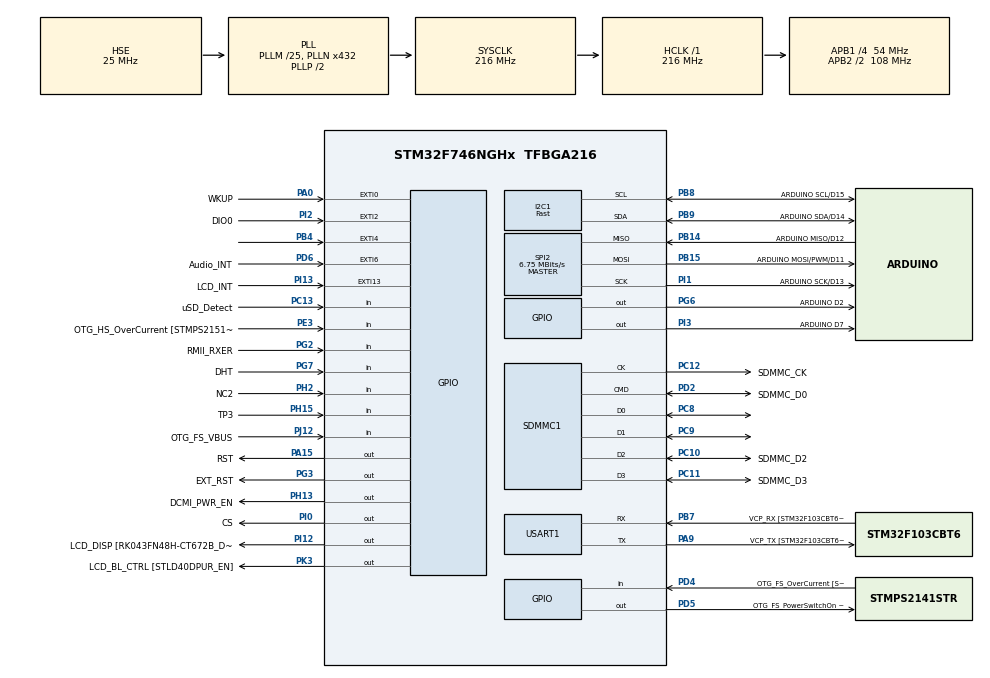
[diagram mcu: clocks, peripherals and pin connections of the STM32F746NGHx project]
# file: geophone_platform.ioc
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Dma.I2C1_RX.0.Direction=DMA_PERIPH_TO_MEMORY
Dma.I2C1_RX.0.FIFOMode=DMA_FIFOMODE_DISABLE
Dma.I2C1_RX.0.Instance=DMA1_Stream0
Dma.I2C1_RX.0.MemDataAlignment=DMA_MDATAALIGN_BYTE
Dma.I2C1_RX.0.MemInc=DMA_MINC_ENABLE
Dma.I2C1_RX.0.Mode=DMA_NORMAL
Dma.I2C1_RX.0.PeriphDataAlignment=DMA_PDATAALIGN_BYTE
Dma.I2C1_RX.0.PeriphInc=DMA_PINC_DISABLE
Dma.I2C1_RX.0.Priority=DMA_PRIORITY_LOW
Dma.I2C1_TX.1.Direction=DMA_MEMORY_TO_PERIPH
Dma.I2C1_TX.1.FIFOMode=DMA_FIFOMODE_DISABLE
Dma.I2C1_TX.1.Instance=DMA1_Stream6
Dma.I2C1_TX.1.MemDataAlignment=DMA_MDATAALIGN_BYTE
Dma.I2C1_TX.1.MemInc=DMA_MINC_ENABLE
Dma.I2C1_TX.1.Mode=DMA_NORMAL
Dma.I2C1_TX.1.PeriphDataAlignment=DMA_PDATAALIGN_BYTE
Dma.I2C1_TX.1.PeriphInc=DMA_PINC_DISABLE
Dma.I2C1_TX.1.Priority=DMA_PRIORITY_LOW
Dma.Request0=I2C1_RX
Dma.Request1=I2C1_TX
Dma.Request2=SPI2_TX
Dma.Request3=SDMMC1_RX
Dma.Request4=SDMMC1_TX
Dma.SDMMC1_RX.3.Direction=DMA_PERIPH_TO_MEMORY
Dma.SDMMC1_RX.3.FIFOMode=DMA_FIFOMODE_ENABLE
Dma.SDMMC1_RX.3.FIFOThreshold=DMA_FIFO_THRESHOLD_FULL
Dma.SDMMC1_RX.3.Instance=DMA2_Stream3
Dma.SDMMC1_RX.3.MemBurst=DMA_MBURST_INC4
Dma.SDMMC1_RX.3.MemDataAlignment=DMA_MDATAALIGN_WORD
Dma.SDMMC1_RX.3.MemInc=DMA_MINC_ENABLE
Dma.SDMMC1_RX.3.Mode=DMA_PFCTRL
Dma.SDMMC1_RX.3.PeriphBurst=DMA_PBURST_INC4
Dma.SDMMC1_RX.3.PeriphDataAlignment=DMA_PDATAALIGN_WORD
Dma.SDMMC1_RX.3.PeriphInc=DMA_PINC_DISABLE
Dma.SDMMC1_RX.3.Priority=DMA_PRIORITY_LOW
Dma.SDMMC1_TX.4.Direction=DMA_MEMORY_TO_PERIPH
Dma.SDMMC1_TX.4.FIFOMode=DMA_FIFOMODE_ENABLE
Dma.SDMMC1_TX.4.FIFOThreshold=DMA_FIFO_THRESHOLD_FULL
Dma.SDMMC1_TX.4.Instance=DMA2_Stream6
Dma.SDMMC1_TX.4.MemBurst=DMA_MBURST_INC4
Dma.SDMMC1_TX.4.MemDataAlignment=DMA_MDATAALIGN_WORD
Dma.SDMMC1_TX.4.MemInc=DMA_MINC_ENABLE
Dma.SDMMC1_TX.4.Mode=DMA_PFCTRL
Dma.SDMMC1_TX.4.PeriphBurst=DMA_PBURST_INC4
Dma.SDMMC1_TX.4.PeriphDataAlignment=DMA_PDATAALIGN_WORD
Dma.SDMMC1_TX.4.PeriphInc=DMA_PINC_DISABLE
Dma.SDMMC1_TX.4.Priority=DMA_PRIORITY_LOW
Dma.SPI2_TX.2.Direction=DMA_MEMORY_TO_PERIPH
Dma.SPI2_TX.2.FIFOMode=DMA_FIFOMODE_DISABLE
Dma.SPI2_TX.2.Instance=DMA1_Stream4
Dma.SPI2_TX.2.MemDataAlignment=DMA_MDATAALIGN_BYTE
Dma.SPI2_TX.2.MemInc=DMA_MINC_ENABLE
Dma.SPI2_TX.2.Mode=DMA_NORMAL
Dma.SPI2_TX.2.PeriphDataAlignment=DMA_PDATAALIGN_BYTE
Dma.SPI2_TX.2.PeriphInc=DMA_PINC_DISABLE
Dma.SPI2_TX.2.Priority=DMA_PRIORITY_LOW
FATFS.BSP.number=1
FATFS.USE_DMA_CODE_SD=1
FATFS0.BSP.STBoard=false
FATFS0.BSP.api=Unknown
FATFS0.BSP.instance=PC13
FATFS0.BSP.ip=GPIO
FATFS0.BSP.mode=Input
FATFS0.BSP.name=Detect_SDIO
FATFS0.BSP.solution=PC13
FREERTOS.Tasks01=defaultTask,24,256,StartDefaultTask,Default,NULL,Dynamic,NULL,NULL
FREERTOS.configTOTAL_HEAP_SIZE=65536
FREERTOS.configUSE_TICKLESS_IDLE=1
I2C1.I2C_Speed_Mode=I2C_Fast
I2C1.Timing=0x6000030D
Mcu.Family=STM32F7
Mcu.Name=STM32F746NGHx
Mcu.Package=TFBGA216
NVIC.DMA1_Stream0_IRQn=true\:5\:0\:false\:false\:true\:true\:false\:true\:true
NVIC.DMA1_Stream4_IRQn=true\:5\:0\:false\:false\:true\:true\:false\:true\:true
NVIC.DMA1_Stream6_IRQn=true\:5\:0\:false\:false\:true\:true\:false\:true\:true
NVIC.DMA2_Stream3_IRQn=true\:5\:0\:false\:false\:true\:true\:false\:true\:true
NVIC.DMA2_Stream6_IRQn=true\:5\:0\:false\:false\:true\:true\:false\:true\:true
NVIC.EXTI0_IRQn=true\:5\:0\:true\:false\:true\:true\:true\:true\:true
NVIC.EXTI2_IRQn=true\:5\:0\:false\:false\:true\:true\:true\:true\:true
NVIC.EXTI4_IRQn=true\:5\:0\:true\:false\:true\:true\:true\:true\:true
NVIC.PriorityGroup=NVIC_PRIORITYGROUP_4
NVIC.RTC_WKUP_IRQn=true\:5\:0\:false\:false\:true\:true\:true\:true\:true
NVIC.SDMMC1_IRQn=true\:5\:0\:false\:false\:true\:true\:true\:true\:true
NVIC.SPI2_IRQn=true\:5\:0\:false\:false\:true\:true\:true\:true\:true
PA0/WKUP.GPIO_Label=WKUP
PA0/WKUP.GPIO_ModeDefaultEXTI=GPIO_MODE_IT_FALLING
PA0/WKUP.Signal=GPXTI0
PA1.GPIO_Label=RMII_REF_CLK [LAN8742A-CZ-TR_REFCLK0]
PA1.Signal=ETH_REF_CLK
PA10.GPIO_Label=OTG_FS_ID
PA10.Signal=USB_OTG_FS_ID
PA11.GPIO_Label=OTG_FS_N
PA11.Signal=USB_OTG_FS_DM
PA12.GPIO_Label=OTG_FS_P
PA12.Signal=USB_OTG_FS_DP
PA13.GPIO_Label=SWDIO
PA13.Mode=Serial_Wire
PA13.Signal=SYS_JTMS-SWDIO
PA14.GPIO_Label=SWCLK
PA14.Mode=Serial_Wire
PA14.Signal=SYS_JTCK-SWCLK
PA15.GPIO_Label=RST
PA15.PinState=GPIO_PIN_SET
PA15.Signal=GPIO_Output
PA2.GPIO_Label=RMII_MDIO [LAN8742A-CZ-TR_MDIO]
PA2.Signal=ETH_MDIO
PA3.GPIO_Label=ULPI_D0 [USB3320C-EZK_D0]
PA3.Signal=USB_OTG_HS_ULPI_D0
PA4.GPIO_Label=DCMI_HSYNC
PA4.Signal=DCMI_HSYNC
PA5.GPIO_Label=ULPI_CLK [USB3320C-EZK_CLKOUT]
PA5.Signal=USB_OTG_HS_ULPI_CK
PA6.Signal=DCMI_PIXCLK
PA7.GPIO_Label=RMII_CRS_DV [LAN8742A-CZ-TR_CRS_DV]
PA7.Signal=ETH_CRS_DV
PA8.GPIO_Label=ARDUINO PWM/D10
PA8.GPIO_ModeDefaultPP=GPIO_MODE_AF_PP
PA8.GPIO_PuPd=GPIO_NOPULL
PA8.GPIO_Speed=GPIO_SPEED_FREQ_LOW
PA8.Signal=S_TIM1_CH1
PA9.GPIO_Label=VCP_TX [STM32F103CBT6_PA3]
PA9.GPIO_Mode=GPIO_MODE_AF_PP
PA9.GPIO_PuPd=GPIO_NOPULL
PA9.GPIO_Speed=GPIO_SPEED_FREQ_LOW
PA9.Mode=Asynchronous
PA9.Signal=USART1_TX
PB0.GPIO_Label=ULPI_D1 [USB3320C-EZK_D1]
PB0.Signal=USB_OTG_HS_ULPI_D1
PB1.GPIO_Label=ULPI_D2 [USB3320C-EZK_D2]
PB1.Signal=USB_OTG_HS_ULPI_D2
PB10.GPIO_Label=ULPI_D3 [USB3320C-EZK_D3]
PB10.Signal=USB_OTG_HS_ULPI_D3
PB11.GPIO_Label=ULPI_D4 [USB3320C-EZK_D4]
PB11.Signal=USB_OTG_HS_ULPI_D4
PB12.GPIO_Label=ULPI_D5 [USB3320C-EZK_D5]
PB12.Signal=USB_OTG_HS_ULPI_D5
PB13.GPIO_Label=ULPI_D6 [USB3320C-EZK_D6]
PB13.Signal=USB_OTG_HS_ULPI_D6
PB14.GPIO_Label=ARDUINO MISO/D12
PB14.GPIO_Mode=GPIO_MODE_AF_PP
PB14.GPIO_PuPd=GPIO_NOPULL
PB14.GPIO_Speed=GPIO_SPEED_FREQ_LOW
PB14.Mode=Full_Duplex_Master
PB14.Signal=SPI2_MISO
PB15.GPIO_Label=ARDUINO MOSI/PWM/D11
PB15.GPIO_Mode=GPIO_MODE_AF_PP
PB15.GPIO_PuPd=GPIO_NOPULL
PB15.GPIO_Speed=GPIO_SPEED_FREQ_LOW
PB15.Mode=Full_Duplex_Master
PB15.Signal=SPI2_MOSI
PB2.Signal=QUADSPI_CLK
PB3.GPIO_Label=SWO
PB3.Signal=SYS_JTDO-SWO
PB4.Signal=GPXTI4
PB5.GPIO_Label=ULPI_D7 [USB3320C-EZK_D7]
PB5.Signal=USB_OTG_HS_ULPI_D7
PB6.GPIO_Label=QSPI_NCS [N25Q128A13EF840E_S]
PB6.Signal=QUADSPI_BK1_NCS
PB7.GPIO_Label=VCP_RX [STM32F103CBT6_PA2]
PB7.GPIO_Mode=GPIO_MODE_AF_PP
PB7.GPIO_PuPd=GPIO_NOPULL
PB7.GPIO_Speed=GPIO_SPEED_FREQ_LOW
PB7.Mode=Asynchronous
PB7.Signal=USART1_RX
PB8.GPIO_Label=ARDUINO SCL/D15
PB8.GPIO_Mode=GPIO_MODE_AF_OD
PB8.GPIO_PuPd=GPIO_NOPULL
PB8.GPIO_Speed=GPIO_SPEED_FREQ_VERY_HIGH
PB8.Mode=I2C
PB8.Signal=I2C1_SCL
PB9.GPIO_Label=ARDUINO SDA/D14
PB9.GPIO_Mode=GPIO_MODE_AF_OD
PB9.GPIO_PuPd=GPIO_NOPULL
PB9.GPIO_Speed=GPIO_SPEED_FREQ_VERY_HIGH
PB9.Mode=I2C
PB9.Signal=I2C1_SDA
PC0.GPIO_Label=ULPI_STP [USB3320C-EZK_STP]
PC0.Signal=USB_OTG_HS_ULPI_STP
PC1.GPIO_Label=RMII_MDC [LAN8742A-CZ-TR_MDC]
PC1.Signal=ETH_MDC
PC10.GPIO_Label=SDMMC_D2
PC10.Mode=SD_4_bits_Wide_bus
PC10.Signal=SDMMC1_D2
PC11.GPIO_Label=SDMMC_D3
PC11.Mode=SD_4_bits_Wide_bus
PC11.Signal=SDMMC1_D3
PC12.GPIO_Label=SDMMC_CK
PC12.Mode=SD_4_bits_Wide_bus
PC12.Signal=SDMMC1_CK
PC13.GPIO_Label=uSD_Detect
PC13.Signal=GPIO_Input
PC14/OSC32_IN.GPIO_Label=RCC_OSC32_IN
PC14/OSC32_IN.Mode=LSE-External-Oscillator
PC14/OSC32_IN.Signal=RCC_OSC32_IN
PC15/OSC32_OUT.GPIO_Label=RCC_OSC32_OUT
PC15/OSC32_OUT.Mode=LSE-External-Oscillator
PC15/OSC32_OUT.Signal=RCC_OSC32_OUT
PC2.GPIO_Label=ULPI_DIR [USB3320C-EZK_DIR]
PC2.Signal=USB_OTG_HS_ULPI_DIR
PC3.GPIO_Label=FMC_SDCKE0 [MT48LC4M32B2B5-6A_CKE]
PC3.Signal=FMC_SDCKE0
PC4.GPIO_Label=RMII_RXD0 [LAN8742A-CZ-TR_RXD0]
PC4.Signal=ETH_RXD0
PC5.GPIO_Label=RMII_RXD1 [LAN8742A-CZ-TR_RXD1]
PC5.Signal=ETH_RXD1
PC6.GPIO_Label=ARDUINO TX/D1
PC6.Signal=USART6_TX
PC7.GPIO_Label=ARDUINO RX/D0
PC7.Signal=USART6_RX
PC8.Mode=SD_4_bits_Wide_bus
PC8.Signal=SDMMC1_D0
PC9.Mode=SD_4_bits_Wide_bus
PC9.Signal=SDMMC1_D1
PD0.GPIO_Label=FMC_D2 [MT48LC4M32B2B5-6A_DQ2]
PD0.Signal=FMC_D2_DA2
PD1.GPIO_Label=FMC_D3 [MT48LC4M32B2B5-6A_DQ3]
PD1.Signal=FMC_D3_DA3
PD10.GPIO_Label=FMC_D15 [MT48LC4M32B2B5-6A_DQ15]
PD10.Signal=FMC_D15_DA15
PD11.GPIO_Label=QSPI_D0 [N25Q128A13EF840E_DQ0]
PD11.Signal=QUADSPI_BK1_IO0
PD12.GPIO_Label=QSPI_D1 [N25Q128A13EF840E_DQ1]
PD12.Signal=QUADSPI_BK1_IO1
PD13.GPIO_Label=QSPI_D3 [N25Q128A13EF840E_DQ3]
PD13.Signal=QUADSPI_BK1_IO3
PD14.GPIO_Label=FMC_D0 [MT48LC4M32B2B5-6A_DQ0]
PD14.Signal=FMC_D0_DA0
PD15.GPIO_Label=FMC_D1 [MT48LC4M32B2B5-6A_DQ1]
PD15.Signal=FMC_D1_DA1
PD2.GPIO_Label=SDMMC_D0
PD2.Mode=SD_4_bits_Wide_bus
PD2.Signal=SDMMC1_CMD
PD3.GPIO_Label=DCMI_D5
PD3.Signal=DCMI_D5
PD4.GPIO_Label=OTG_FS_OverCurrent [STMPS2141STR_Fault]
PD4.Signal=GPIO_Input
PD5.GPIO_Label=OTG_FS_PowerSwitchOn [STMPS2141STR_EN]
PD5.PinState=GPIO_PIN_SET
PD5.Signal=GPIO_Output
PD6.GPIO_Label=Audio_INT
PD6.GPIO_ModeDefaultEXTI=GPIO_MODE_EVT_RISING
PD6.Signal=GPXTI6
PD7.GPIO_Label=SPDIF_RX0 [74LVC1G04SE_4]
PD7.Signal=SPDIFRX_IN0
PD8.GPIO_Label=FMC_D13 [MT48LC4M32B2B5-6A_DQ13]
PD8.Signal=FMC_D13_DA13
PD9.GPIO_Label=FMC_D14 [MT48LC4M32B2B5-6A_DQ14]
PD9.Signal=FMC_D14_DA14
PE0.GPIO_Label=FMC_NBL0 [MT48LC4M32B2B5-6A_DQM0]
PE0.Signal=FMC_NBL0
PE1.GPIO_Label=FMC_NBL1 [MT48LC4M32B2B5-6A_DQM1]
PE1.Signal=FMC_NBL1
PE10.GPIO_Label=FMC_D7 [MT48LC4M32B2B5-6A_DQ7]
PE10.Signal=FMC_D7_DA7
PE11.GPIO_Label=FMC_D8 [MT48LC4M32B2B5-6A_DQ8]
PE11.Signal=FMC_D8_DA8
PE12.GPIO_Label=FMC_D9 [MT48LC4M32B2B5-6A_DQ9]
PE12.Signal=FMC_D9_DA9
PE13.GPIO_Label=FMC_D10 [MT48LC4M32B2B5-6A_DQ10]
PE13.Signal=FMC_D10_DA10
PE14.GPIO_Label=FMC_D11 [MT48LC4M32B2B5-6A_DQ11]
PE14.Signal=FMC_D11_DA11
PE15.GPIO_Label=FMC_D12 [MT48LC4M32B2B5-6A_DQ12]
PE15.Signal=FMC_D12_DA12
PE2.GPIO_Label=QSPI_D2 [N25Q128A13EF840E_DQ2]
PE2.Signal=QUADSPI_BK1_IO2
PE3.GPIO_Label=OTG_HS_OverCurrent [STMPS2151STR_FAULT]
PE3.Signal=GPIO_Input
PE4.GPIO_Label=LCD_B0 [RK043FN48H-CT672B_B0]
PE4.Signal=LTDC_B0
PE5.GPIO_Label=DCMI_D6
PE5.Signal=DCMI_D6
PE6.GPIO_Label=DCMI_D7
PE6.Signal=DCMI_D7
PE7.GPIO_Label=FMC_D4 [MT48LC4M32B2B5-6A_DQ4]
PE7.Signal=FMC_D4_DA4
PE8.GPIO_Label=FMC_D5 [MT48LC4M32B2B5-6A_DQ5]
PE8.Signal=FMC_D5_DA5
PE9.GPIO_Label=FMC_D6 [MT48LC4M32B2B5-6A_DQ6]
PE9.Signal=FMC_D6_DA6
PF0.GPIO_Label=FMC_A0 [MT48LC4M32B2B5-6A_A0]
PF0.Signal=FMC_A0
PF1.GPIO_Label=FMC_A1 [MT48LC4M32B2B5-6A_A1]
PF1.Signal=FMC_A1
PF10.GPIO_Label=ARDUINO A1
PF10.GPIO_Mode=GPIO_MODE_ANALOG
PF10.GPIO_PuPd=GPIO_NOPULL
PF10.Signal=ADC3_IN8
PF11.GPIO_Label=FMC_SDNRAS [MT48LC4M32B2B5-6A_RAS]
PF11.Signal=FMC_SDNRAS
PF12.GPIO_Label=FMC_A6 [MT48LC4M32B2B5-6A_A6]
PF12.Signal=FMC_A6
PF13.GPIO_Label=FMC_A7 [MT48LC4M32B2B5-6A_A7]
PF13.Signal=FMC_A7
PF14.GPIO_Label=FMC_A8 [MT48LC4M32B2B5-6A_A8]
PF14.Signal=FMC_A8
PF15.GPIO_Label=FMC_A9 [MT48LC4M32B2B5-6A_A9]
PF15.Signal=FMC_A9
PF2.GPIO_Label=FMC_A2 [MT48LC4M32B2B5-6A_A2]
PF2.Signal=FMC_A2
PF3.GPIO_Label=FMC_A3 [MT48LC4M32B2B5-6A_A3]
PF3.Signal=FMC_A3
PF4.GPIO_Label=FMC_A4 [MT48LC4M32B2B5-6A_A4]
PF4.Signal=FMC_A4
PF5.GPIO_Label=FMC_A5 [MT48LC4M32B2B5-6A_A5]
PF5.Signal=FMC_A5
PF6.GPIO_Label=ARDUINO A5
PF6.GPIO_Mode=GPIO_MODE_ANALOG
PF6.GPIO_PuPd=GPIO_NOPULL
PF6.Signal=ADC3_IN4
PF7.GPIO_Label=ARDUINO A4
PF7.GPIO_Mode=GPIO_MODE_ANALOG
PF7.GPIO_PuPd=GPIO_NOPULL
PF7.Signal=ADC3_IN5
PF8.GPIO_Label=ARDUINO A3
PF8.GPIO_Mode=GPIO_MODE_ANALOG
PF8.GPIO_PuPd=GPIO_NOPULL
PF8.Signal=ADC3_IN6
PF9.GPIO_Label=ARDUINO A2
PF9.GPIO_Mode=GPIO_MODE_ANALOG
PF9.GPIO_PuPd=GPIO_NOPULL
PF9.Signal=ADC3_IN7
PG0.GPIO_Label=FMC_A10 [MT48LC4M32B2B5-6A_A10]
PG0.Signal=FMC_A10
PG1.GPIO_Label=FMC_A11 [MT48LC4M32B2B5-6A_A11]
PG1.Signal=FMC_A11
PG10.GPIO_Label=SAI2_SDB [WM8994ECS/R_ADCDAT1]
PG10.Signal=SAI2_SD_B
PG11.GPIO_Label=RMII_TX_EN [LAN8742A-CZ-TR_TXEN]
PG11.Signal=ETH_TX_EN
PG12.GPIO_Label=LCD_B4 [RK043FN48H-CT672B_B4]
PG12.Signal=LTDC_B4
PG13.GPIO_Label=RMII_TXD0 [LAN8742A-CZ-TR_TXD0]
PG13.Signal=ETH_TXD0
PG14.GPIO_Label=RMII_TXD1 [LAN8742A-CZ-TR_TXD1]
PG14.Signal=ETH_TXD1
PG15.GPIO_Label=FMC_SDNCAS [MT48LC4M32B2B5-6A_CAS]
PG15.Signal=FMC_SDNCAS
PG2.GPIO_Label=RMII_RXER
PG2.Signal=GPIO_Input
PG3.GPIO_Label=EXT_RST
PG3.Signal=GPIO_Output
PG4.GPIO_Label=FMC_BA0 [MT48LC4M32B2B5-6A_BA0]
PG4.Signal=FMC_A14_BA0
PG5.GPIO_Label=FMC_BA1 [MT48LC4M32B2B5-6A_BA1]
PG5.Signal=FMC_A15_BA1
PG6.GPIO_Label=ARDUINO D2
PG6.Signal=GPIO_Output
PG7.GPIO_Label=DHT
PG7.Signal=GPIO_Input
PG8.GPIO_Label=FMC_SDCLK [MT48LC4M32B2B5-6A_CLK]
PG8.Signal=FMC_SDCLK
PG9.GPIO_Label=DCMI_VSYNC
PG9.Signal=DCMI_VSYNC
PH0/OSC_IN.GPIO_Label=OSC_25M [NZ2520SB-25.00M_OUT]
PH0/OSC_IN.Mode=HSE-External-Oscillator
PH0/OSC_IN.Signal=RCC_OSC_IN
PH1/OSC_OUT.Mode=HSE-External-Oscillator
PH1/OSC_OUT.Signal=RCC_OSC_OUT
PH10.GPIO_Label=DCMI_D1
PH10.Signal=DCMI_D1
PH11.GPIO_Label=DCMI_D2
PH11.Signal=DCMI_D2
PH12.GPIO_Label=DCMI_D3
PH12.Signal=DCMI_D3
PH13.GPIO_Label=DCMI_PWR_EN
PH13.Signal=GPIO_Output
PH14.GPIO_Label=DCMI_D4
PH14.Signal=DCMI_D4
PH15.GPIO_Label=TP3
PH15.Signal=GPIO_Input
PH2.GPIO_Label=NC2
PH2.Signal=GPIO_Input
PH3.GPIO_Label=FMC_SDNE0 [MT48LC4M32B2B5-6A_CS]
PH3.Signal=FMC_SDNE0
PH4.GPIO_Label=ULPI_NXT [USB3320C-EZK_NXT]
PH4.Signal=USB_OTG_HS_ULPI_NXT
PH5.GPIO_Label=FMC_SDNME [MT48LC4M32B2B5-6A_WE]
PH5.Signal=FMC_SDNWE
PH6.GPIO_Label=ARDUINO PWM/D6
PH6.Signal=S_TIM12_CH1
PH7.GPIO_Label=LCD_SCL [RK043FN48H-CT672B_SCL]
PH7.Signal=I2C3_SCL
PH8.GPIO_Label=LCD_SDA [RK043FN48H-CT672B_SDA]
PH8.Signal=I2C3_SDA
PH9.GPIO_Label=DCMI_D0
PH9.Signal=DCMI_D0
PI0.GPIO_Label=CS
PI0.PinState=GPIO_PIN_SET
PI0.Signal=GPIO_Output
PI1.GPIO_Label=ARDUINO SCK/D13
PI1.GPIO_Mode=GPIO_MODE_AF_PP
PI1.GPIO_PuPd=GPIO_NOPULL
PI1.GPIO_Speed=GPIO_SPEED_FREQ_LOW
PI1.Mode=Full_Duplex_Master
PI1.Signal=SPI2_SCK
PI10.GPIO_Label=LCD_HSYNC [RK043FN48H-CT672B_HSYNC]
PI10.Signal=LTDC_HSYNC
PI12.GPIO_Label=LCD_DISP [RK043FN48H-CT672B_DISP] 
PI12.Signal=GPIO_Output
PI13.GPIO_Label=LCD_INT
PI13.GPIO_ModeDefaultEXTI=GPIO_MODE_EVT_RISING
PI13.Signal=GPXTI13
PI14.GPIO_Label=LCD_CLK [RK043FN48H-CT672B_CLK]
PI14.Signal=LTDC_CLK
PI15.GPIO_Label=LCD_R0 [RK043FN48H-CT672B_R0]
PI15.Signal=LTDC_R0
PI2.GPIO_Label=DIO0
PI2.Signal=GPXTI2
PI3.GPIO_Label=ARDUINO D7
PI3.Signal=GPIO_Output
PI4.GPIO_Label=SAI2_MCLKA [WM8994ECS/R_MCLK1]
PI4.Signal=SAI2_MCLK_A
PI5.GPIO_Label=SAI2_SCKA [WM8994ECS/R_BCLK1]
PI5.Signal=SAI2_SCK_A
PI6.GPIO_Label=SAI2_SDA [WM8994ECS/R_DACDAT1]
PI6.Signal=SAI2_SD_A
PI7.GPIO_Label=SAI2_FSA [WM8994ECS/R_LRCLK1]
PI7.Signal=SAI2_FS_A
PI8.GPIO_Label=NC1 [TP2]
PI8.Signal=RTC_TS
PI9.GPIO_Label=LCD_VSYNC [RK043FN48H-CT672B_VSYNC]
PI9.Signal=LTDC_VSYNC
PJ0.GPIO_Label=LCD_R1 [RK043FN48H-CT672B_R1]
PJ0.Signal=LTDC_R1
PJ1.GPIO_Label=LCD_R2 [RK043FN48H-CT672B_R2]
PJ1.Signal=LTDC_R2
PJ10.GPIO_Label=LCD_G3 [RK043FN48H-CT672B_G3]
PJ10.Signal=LTDC_G3
PJ11.GPIO_Label=LCD_G4 [RK043FN48H-CT672B_G4]
PJ11.Signal=LTDC_G4
PJ12.GPIO_Label=OTG_FS_VBUS
PJ12.Signal=GPIO_Input
PJ13.GPIO_Label=LCD_B1 [RK043FN48H-CT672B_B1]
PJ13.Signal=LTDC_B1
PJ14.GPIO_Label=LCD_B2 [RK043FN48H-CT672B_B2]
PJ14.Signal=LTDC_B2
PJ15.GPIO_Label=LCD_B3 [RK043FN48H-CT672B_B3]
PJ15.Signal=LTDC_B3
PJ2.GPIO_Label=LCD_R3 [RK043FN48H-CT672B_R3]
PJ2.Signal=LTDC_R3
PJ3.GPIO_Label=LCD_R4 [RK043FN48H-CT672B_R4]
PJ3.Signal=LTDC_R4
PJ4.GPIO_Label=LCD_R5 [RK043FN48H-CT672B_R5]
PJ4.Signal=LTDC_R5
PJ5.GPIO_Label=LCD_R6 [RK043FN48H-CT672B_R6]
PJ5.Signal=LTDC_R6
PJ6.GPIO_Label=LCD_R7 [RK043FN48H-CT672B_R7]
PJ6.Signal=LTDC_R7
PJ7.GPIO_Label=LCD_G0 [RK043FN48H-CT672B_G0]
PJ7.Signal=LTDC_G0
PJ8.GPIO_Label=LCD_G1 [RK043FN48H-CT672B_G1]
PJ8.Signal=LTDC_G1
PJ9.GPIO_Label=LCD_G2 [RK043FN48H-CT672B_G2]
PJ9.Signal=LTDC_G2
PK0.GPIO_Label=LCD_G5 [RK043FN48H-CT672B_G5]
PK0.Signal=LTDC_G5
PK1.GPIO_Label=LCD_G6 [RK043FN48H-CT672B_G6]
PK1.Signal=LTDC_G6
PK2.GPIO_Label=LCD_G7 [RK043FN48H-CT672B_G7]
PK2.Signal=LTDC_G7
PK3.GPIO_Label=LCD_BL_CTRL [STLD40DPUR_EN]
PK3.Signal=GPIO_Output
PK4.GPIO_Label=LCD_B5 [RK043FN48H-CT672B_B5]
PK4.Signal=LTDC_B5
PK5.GPIO_Label=LCD_B6 [RK043FN48H-CT672B_B6]
PK5.Signal=LTDC_B6
PK6.GPIO_Label=LCD_B7 [RK043FN48H-CT672B_B7]
PK6.Signal=LTDC_B7
PK7.GPIO_Label=LCD_DE [RK043FN48H-CT672B_DE]
PK7.Signal=LTDC_DE
ProjectManager.HeapSize=0x4000
ProjectManager.StackSize=0x800
ProjectManager.TargetToolchain=STM32CubeIDE
RCC.AHBFreq_Value=216000000
RCC.APB1CLKDivider=RCC_HCLK_DIV4
RCC.APB1Freq_Value=54000000
RCC.APB1TimFreq_Value=108000000
RCC.APB2CLKDivider=RCC_HCLK_DIV2
RCC.APB2Freq_Value=108000000
RCC.APB2TimFreq_Value=216000000
RCC.CortexFreq_Value=216000000
RCC.HCLKFreq_Value=216000000
RCC.HSE_VALUE=25000000
RCC.HSI_VALUE=16000000
RCC.PLLM=25
RCC.PLLN=432
RCC.PLLQ=9
RCC.PLLSourceVirtual=RCC_PLLSOURCE_HSE
RCC.RTCClockSelection=RCC_RTCCLKSOURCE_LSE
RCC.SDMMCClockSelection=RCC_SDMMC1CLKSOURCE_CLK48
RCC.SYSCLKFreq_VALUE=216000000
RCC.SYSCLKSource=RCC_SYSCLKSOURCE_PLLCLK
RCC.USBFreq_Value=48000000
RCC.VCOOutputFreq_Value=432000000
SH.FMC_A0.0=FMC_A0
SH.FMC_A1.0=FMC_A1
SH.FMC_A10.0=FMC_A10
SH.FMC_A11.0=FMC_A11
SH.FMC_A14_BA0.0=FMC_BA0
SH.FMC_A15_BA1.0=FMC_BA1
SH.FMC_A2.0=FMC_A2
SH.FMC_A3.0=FMC_A3
SH.FMC_A4.0=FMC_A4
SH.FMC_A5.0=FMC_A5
SH.FMC_A6.0=FMC_A6
SH.FMC_A7.0=FMC_A7
SH.FMC_A8.0=FMC_A8
SH.FMC_A9.0=FMC_A9
SH.FMC_D0_DA0.0=FMC_D0
SH.FMC_D10_DA10.0=FMC_D10
SH.FMC_D11_DA11.0=FMC_D11
SH.FMC_D12_DA12.0=FMC_D12
SH.FMC_D13_DA13.0=FMC_D13
SH.FMC_D14_DA14.0=FMC_D14
SH.FMC_D15_DA15.0=FMC_D15
SH.FMC_D1_DA1.0=FMC_D1
SH.FMC_D2_DA2.0=FMC_D2
SH.FMC_D3_DA3.0=FMC_D3
SH.FMC_D4_DA4.0=FMC_D4
SH.FMC_D5_DA5.0=FMC_D5
SH.FMC_D6_DA6.0=FMC_D6
SH.FMC_D7_DA7.0=FMC_D7
SH.FMC_D8_DA8.0=FMC_D8
SH.FMC_D9_DA9.0=FMC_D9
SH.FMC_NBL0.0=FMC_NBL0
SH.FMC_NBL1.0=FMC_NBL1
SH.FMC_SDCLK.0=FMC_SDCLK
SH.FMC_SDNCAS.0=FMC_SDNCAS
SH.FMC_SDNRAS.0=FMC_SDNRAS
SH.FMC_SDNWE.0=FMC_SDNWE
SH.S_TIM12_CH1.0=TIM12_CH1
SH.S_TIM1_CH1.0=TIM1_CH1
SPI2.BaudRatePrescaler=SPI_BAUDRATEPRESCALER_8
SPI2.CalculateBaudRate=6.75 MBits/s
SPI2.DataSize=SPI_DATASIZE_8BIT
SPI2.Direction=SPI_DIRECTION_2LINES
SPI2.Mode=SPI_MODE_MASTER
SPI2.NSSPMode=SPI_NSS_PULSE_DISABLE
SPI2.VirtualType=VM_MASTER
USART1.VirtualMode-Asynchronous=VM_ASYNC
VP_FATFS_VS_SDIO.Mode=SDIO
VP_FREERTOS_VS_CMSIS_V2.Mode=CMSIS_V2
VP_RTC_VS_RTC_Activate.Mode=RTC_Enabled
VP_RTC_VS_RTC_Calendar.Mode=RTC_Calendar
VP_RTC_VS_RTC_WakeUp_intern.Mode=WakeUp
board=STM32F746G-DISCO

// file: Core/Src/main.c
/* USER CODE BEGIN Header */
/**
  ******************************************************************************
  * @file           : main.c
  * @brief          : Main program body
  ******************************************************************************
  * @attention
  *
  * Copyright (c) 2025 STMicroelectronics.
  * All rights reserved.
  *
  * This software is licensed under terms that can be found in the LICENSE file
  * in the root directory of this software component.
  * If no LICENSE file comes with this software, it is provided AS-IS.
  *
  ******************************************************************************
  */
/* USER CODE END Header */
#include "main.h"
#include "cmsis_os.h"
#include "fatfs.h"
#include "rtc.h"
#include <string.h>
#include <stdio.h>

/* drivers */
#include "ADS1115_dma.h"
#include "MPU6050_dma.h"
#include "MCP4725_dma.h"
#include "LoRa_dma.h"
#include "DHT11.h"

/* extern handles from CubeMX */
extern I2C_HandleTypeDef hi2c1;
extern SPI_HandleTypeDef hspi2;
extern UART_HandleTypeDef huart1;
extern SD_HandleTypeDef hsd1;
extern RTC_HandleTypeDef hrtc;

/* --- RTOS objects --- */
static osMutexId_t i2c_mutex = NULL;

/* semaphores used by drivers (binary semaphores used to signal DMA completion) */
static osSemaphoreId_t sem_ads = NULL;
static osSemaphoreId_t sem_mpu = NULL;
static osSemaphoreId_t sem_mcp = NULL;
static osSemaphoreId_t sem_lora_tx = NULL;

/* queues */
typedef enum { LOGTYPE_ACQ=1, LOGTYPE_IMU, LOGTYPE_HEALTH, LOGTYPE_EVENT } LogType_t;
typedef struct {
    LogType_t type;
    uint32_t timestamp; /* unix or epoch seconds from RTC */
    uint8_t *data;      /* pointer to payload (must be allocated by producer) */
    uint16_t len;
} LogMsg_t;

static osMessageQueueId_t logQueue = NULL;

/* Task prototypes */
static void InitTask(void *arg);
static void AcquisitionTask(void *arg);
static void IMUTask(void *arg);
static void CommTask(void *arg);
static void LoggingTask(void *arg);
static void HealthTask(void *arg);
static void TimerDaemonTask(void *arg);

/* helper: get RTC timestamp (seconds since 1970 not implemented, provide simple YMDHMS) */
static void get_rtc_time_string(char *buf, size_t len)
{
    RTC_TimeTypeDef sTime;
    RTC_DateTypeDef sDate;
    HAL_RTC_GetTime(&hrtc, &sTime, RTC_FORMAT_BIN);
    HAL_RTC_GetDate(&hrtc, &sDate, RTC_FORMAT_BIN); // must call GetDate after GetTime
    snprintf(buf, len, "%04u-%02u-%02u %02u:%02u:%02u",
             2000 + sDate.Year, sDate.Month, sDate.Date,
             sTime.Hours, sTime.Minutes, sTime.Seconds);
}

/* printf redirection */
int __io_putchar(int ch) {
    uint8_t c = (uint8_t)ch;
    HAL_UART_Transmit(&huart1, &c, 1, HAL_MAX_DELAY);
    return ch;
}
int fputc(int ch, FILE *f) { return __io_putchar(ch); }

/* Forward HAL callbacks (single place) */
void HAL_I2C_MasterTxCpltCallback(I2C_HandleTypeDef *hi2c)
{
    MCP4725_DMA_TxCpltCallback(hi2c);
}
void HAL_I2C_MemRxCpltCallback(I2C_HandleTypeDef *hi2c)
{
    /* forward to driver callbacks which set flags/semaphores */
    ADS1115_DMA_RxCpltCallback(hi2c);      // driver should check hi2c pointer
    MPU6050_DMA_I2C_RxCpltCallback(hi2c);
    MCP4725_DMA_RxCpltCallback(hi2c);      // if you implemented callback for write/read
}

void HAL_I2C_ErrorCallback(I2C_HandleTypeDef *hi2c)
{
    ADS1115_DMA_ErrorCallback(hi2c);
    MPU6050_DMA_I2C_ErrorCallback(hi2c);
    MCP4725_DMA_ErrorCallback(hi2c);
}

/* SPI TX complete -> forward to LoRa driver */
void HAL_SPI_TxCpltCallback(SPI_HandleTypeDef *hspi)
{
    LoRa_SPI_TxCplt_Callback(hspi);
}

/* GPIO exti forwarder: DIO0 -> LoRa, Comparator (PA0) -> notify Acquisition */
void HAL_GPIO_EXTI_Callback(uint16_t GPIO_Pin)
{
    if (GPIO_Pin == LORA_DIO0_Pin) {
        LoRa_DIO0_Callback();
    }
    /* comparator LM393 output wired to PA0 -> notify AcquisitionTask */
    if (GPIO_Pin == GPIO_PIN_0) {
        BaseType_t xHigherPriorityTaskWoken = pdFALSE;
        /* If using CMSIS v2, use osThreadFlagsSet from ISR-safe wrapper:
           osThreadFlagsSet doesn't have FROM_ISR variant; we will use a direct-to-task
           notify simulation: in our design we will set an IRQ flag through HAL and then
           use osThreadFlagsSet from main context; to keep simple, we'll use a global flag and a semaphore. */
        /* Simpler approach: call HAL_GPIO_TogglePin or set a flag and wake via IRQ semaphore - implement below as example */
        /* Here just print debug (keep ISR short) */
        /* Do minimal work, main tasks will observe event via EXTI and driver states */
    }
}

/* Utility: push log message to queue (allocates payload copy) */
static int push_log_message(LogType_t type, const void *buf, uint16_t len)
{
    if (logQueue == NULL) return -1;
    LogMsg_t msg;
    msg.type = type;
    msg.len = len;
    msg.data = NULL;
    /* allocate memory for payload */
    if (len > 0) {
        msg.data = pvPortMalloc(len);
        if (!msg.data) return -2;
        memcpy(msg.data, buf, len);
    }
    /* set timestamp from RTC (seconds not implemented, use placeholder) */
    RTC_TimeTypeDef t; RTC_DateTypeDef d;
    HAL_RTC_GetTime(&hrtc, &t, RTC_FORMAT_BIN);
    HAL_RTC_GetDate(&hrtc, &d, RTC_FORMAT_BIN);
    /* simple encoded timestamp: HHMMSSDDMMYY */
    msg.timestamp = (t.Hours << 24) | (t.Minutes << 16) | (t.Seconds << 8) | (d.Date & 0xFF);

    if (osMessageQueuePut(logQueue, &msg, 0, 0) != osOK) {
        /* queue full - free allocated */
        if (msg.data) vPortFree(msg.data);
        return -3;
    }
    return 0;
}

/* -------------------- Task implementations -------------------- */

/* InitTask: lightweight init then exit (or suspend) */
static void InitTask(void *arg)
{
    (void)arg;
    printf("InitTask: starting drivers\n");

    /* Initialize drivers - ensure i2c_mutex and semaphores already created before calling these if drivers expect them */
    ADS1115_Init(&hi2c1, ADS1115_ADDRESS_GND, ADS_PGA_2_048, ADS_DR_250SPS);
    MPU6050_DMA_Init();
    MCP4725_Init(&hi2c1, 0x60); /* adjust addr if necessary */

    /* Link semaphores to drivers (driver headers must provide these) */
    ADS1115_SetSemaphore(sem_ads);
    MPU6050_SetSemaphore(sem_mpu);
    MCP4725_SetSemaphore(sem_mcp);
    LoRa_SetTxSemaphore(sem_lora_tx);

    /* Link i2c mutex */
    ADS1115_SetI2CMutex(i2c_mutex);
    MPU6050_SetI2CMutex(i2c_mutex);
    MCP4725_SetI2CMutex(i2c_mutex);

    /* Init LoRa and set frequency */
    if (LoRa_Init() == 0) {
        LoRa_SetFrequency(433000000);
        printf("InitTask: LoRa init OK\n");
    } else {
        printf("InitTask: LoRa init failed\n");
    }

    /* Optionally create a test packet here or signal other tasks */
    printf("InitTask: done, suspending self\n");
    vTaskSuspend(NULL); /* suspend init task */
}

/* AcquisitionTask: highest priority. Woken by EXTI (external comparator) via osThreadFlags or by a queued event.
   This implementation demonstrates: when woken, perform ADS1115 + MPU read, push to log queue, attempt LoRa TX.
*/
static void AcquisitionTask(void *arg)
{
    (void)arg;
    const TickType_t wait = pdMS_TO_TICKS(2000);

    for (;;) {
        /* Wait for notification/flag - for simplicity use osThreadFlagsWait,
           but if you plan to notify from ISR use osThreadFlagsSet(task_id, flags).
           We'll sleep and check a simple hardware flag - replace with real notify */
        /* In real deployment: use direct-to-task notify from ISR. Here: poll (simple) */
        osThreadFlagsWait(0x0001, osFlagsWaitAny, osWaitForever); // placeholder; ISR should call osThreadFlagsSet(acqTask, 0x1)
        printf("AcquisitionTask: triggered\n");

        /* Read ADS1115 (blocking wrapper using DMA) */
        int16_t raw;
        if (ADS1115_ReadRaw_DMA_Blocking(&raw, 500) == 0) {
            float volts = 0;
            ADS1115_ReadVoltage_DMA_Blocking(& (float){0}, 1); // optionally get volts
            printf("Acq: ADS raw=%d\n", raw);
        } else {
            printf("Acq: ADS1115 read failed\n");
        }

        /* Read IMU via DMA (start and wait for semaphore set by MPU callback) */
        if (osMutexAcquire(i2c_mutex, pdMS_TO_TICKS(200)) == osOK) {
            if (MPU6050_DMA_StartRead() == HAL_OK) {
                /* wait on sem_mpu (driver should give sem on RxCplt) */
                if (osSemaphoreAcquire(sem_mpu, wait) == osOK) {
                    MPU6050_Data_t d;
                    MPU6050_DMA_ProcessData(&d);
                    printf("Acq: IMU acc %.3f %.3f %.3f\n", d.acc_x_g, d.acc_y_g, d.acc_z_g);
                    /* pack a small packet to send via LoRa and to log */
                    uint8_t payload[32];
                    int n = snprintf((char*)payload, sizeof(payload), "T%u A:%.3f,%.3f,%.3f",
                                     (unsigned)HAL_GetTick(), d.acc_x_g, d.acc_y_g, d.acc_z_g);
                    /* send via LoRa (non-blocking internal, but our LoRa_Transmit_DMA blocks until tx_done) */
                    if (LoRa_Transmit_DMA(payload, (uint16_t)n, 2000) == 0) {
                        printf("Acq: LoRa TX OK\n");
                    } else {
                        printf("Acq: LoRa TX failed\n");
                    }
                    /* push to log queue */
                    push_log_message(LOGTYPE_ACQ, payload, (uint16_t)n);
                } else {
                    printf("Acq: MPU timeout\n");
                }
            } else {
                printf("Acq: MPU start read failed\n");
            }
            osMutexRelease(i2c_mutex);
        } else {
            printf("Acq: i2c_mutex busy\n");
        }

        /* After acquisition, wait some settling time or go back to sleep until next notify */
    }
}

/* IMUTask: separate consumer that may perform continuous IMU processing when acquisition is active */
static void IMUTask(void *arg)
{
    (void)arg;
    for (;;) {
        /* Example: periodic health-check read of IMU or use another notify from acquisition */
        osDelay(1000);
    }
}

/* CommTask: responsible for higher-level LoRa RX processing, and responding to gateway commands.
   When LoRa IRQ indicates packet ready, call LoRa_read_payload etc. */
static void CommTask(void *arg)
{
    (void)arg;
    uint8_t rxbuf[256];
    for (;;) {
        /* poll for RX ready */
        if (LoRa_receive_ready()) {
            int n = LoRa_read_payload(rxbuf, sizeof(rxbuf));
            if (n > 0) {
                rxbuf[n] = 0;
                printf("CommTask: received %d bytes: %s\n", n, rxbuf);
                /* handle commands: change threshold -> write MCP4725 via I2C; collect SD files -> transmit back etc. */
                /* For example: if command starts with "TH:" followed by value -> parse and set MCP4725 */
                if (strncmp((char*)rxbuf, "TH:", 3) == 0) {
                    int v = atoi((char*)&rxbuf[3]);
                    /* convert v into DAC raw (0..4095) depending on Vref 3.3V */
                    uint16_t dac = (uint16_t)((v/3.3f) * 4095.0f);
                    if (osMutexAcquire(i2c_mutex, pdMS_TO_TICKS(200)) == osOK) {
                        MCP4725_SetValue(dac); /* assume blocking write */
                        osMutexRelease(i2c_mutex);
                    }
                }
            }
        }
        osDelay(50);
    }
}

/* LoggingTask: sole task writing to SD card. Receives LogMsg_t from producers. */
static void LoggingTask(void *arg)
{
    (void)arg;
    LogMsg_t msg;
    FRESULT fres;
    for (;;) {
        if (osMessageQueueGet(logQueue, &msg, NULL, osWaitForever) == osOK) {
            /* prepare filename and folder using RTC */
            char timestr[64];
            get_rtc_time_string(timestr, sizeof(timestr));
            char fname[128];
            /* choose folder by type */
            const char *folder = (msg.type == LOGTYPE_ACQ) ? "ACQ" :
                                 (msg.type == LOGTYPE_IMU) ? "IMU" :
                                 (msg.type == LOGTYPE_HEALTH) ? "HLT" : "EVT";
            /* create folder and filename e.g., /ACQ/2025-10-31_12-00-00.log */
            snprintf(fname, sizeof(fname), "%s/%s.log", folder, timestr);

            /* open file for append */
            FIL f;
            /* create folder if necessary - f_mkdir */
            char folderpath[64];
            snprintf(folderpath, sizeof(folderpath), "%s", folder);
            f_mkdir(folderpath); // ignore error if exists

            char filepath[160];
            snprintf(filepath, sizeof(filepath), "%s/%08lu.log", folder, (unsigned long)HAL_GetTick());
            if (f_open(&f, filepath, FA_CREATE_ALWAYS | FA_WRITE) == FR_OK) {
                UINT bw;
                /* write timestamp + data */
                f_write(&f, timestr, strlen(timestr), &bw);
                f_write(&f, " ", 1, &bw);
                if (msg.len > 0 && msg.data) {
                    f_write(&f, msg.data, msg.len, &bw);
                }
                f_write(&f, "\r\n", 2, &bw);
                f_close(&f);
                printf("LoggingTask: wrote %s\n", filepath);
            } else {
                printf("LoggingTask: f_open failed for %s\n", filepath);
            }
            if (msg.data) vPortFree(msg.data);
        }
    }
}

/* HealthTask: periodic health monitoring and DHT11 reading */
static void HealthTask(void *arg)
{
    (void)arg;
    DHT_DataTypedef dht;
    for (;;) {
        /* read DHT */
        if (DWT_Delay_Init() == 0) {
            DHT_GetData(&dht);
            if (dht.valid) {
                char buf[64];
                int n = snprintf(buf, sizeof(buf), "T:%.1f H:%.1f", dht.Temperature, dht.Humidity);
                push_log_message(LOGTYPE_HEALTH, buf, (uint16_t)n);
                printf("Health: %s\n", buf);
            } else {
                printf("Health: DHT read failed\n");
            }
        }
        /* battery check, memory, etc. could be added here */
        osDelay(120000); /* every 2 minutes */
    }
}

/* TimerDaemonTask: housekeeping timers & BOLT features */
static void TimerDaemonTask(void *arg)
{
    (void)arg;
    for (;;) {
        /* Run periodic maintenance: rotate logs, check SD space, reschedule tasks, perform periodic calibration */
        osDelay(1000);
    }
}

/* -------------------- main() -------------------- */
int main(void)
{
    /* HAL init */
    HAL_Init();
    SystemClock_Config();

    /* init peripherals from CubeMX */
    MX_GPIO_Init();
    MX_DMA_Init();
    MX_I2C1_Init();
    MX_USART1_UART_Init();
    MX_SPI2_Init();
    MX_SDMMC1_SD_Init();
    MX_FATFS_Init();
    MX_RTC_Init();

    printf("System boot\n");

    /* RTOS kernel init */
    osKernelInitialize();

    /* create synchronization objects BEFORE tasks that will use them */
    /* create i2c mutex */
    i2c_mutex = osMutexNew(NULL);

    /* semaphores - binary (count 0) */
    sem_ads = osSemaphoreNew(1, 0, NULL);
    sem_mpu = osSemaphoreNew(1, 0, NULL);
    sem_mcp = osSemaphoreNew(1, 0, NULL);
    sem_lora_tx = osSemaphoreNew(1, 0, NULL);

    /* message queue for logging */
    logQueue = osMessageQueueNew(32, sizeof(LogMsg_t), NULL);

    /* create tasks */
    const osThreadAttr_t init_attr = { .name="InitTask", .priority=osPriorityHigh, .stack_size=2048 };
    osThreadNew(InitTask, NULL, &init_attr);

    const osThreadAttr_t acq_attr = { .name="AcqTask", .priority=osPriorityRealtime, .stack_size=4096 };
    osThreadNew(AcquisitionTask, NULL, &acq_attr);

    const osThreadAttr_t imu_attr = { .name="IMUTask", .priority=osPriorityHigh, .stack_size=2048 };
    osThreadNew(IMUTask, NULL, &imu_attr);

    const osThreadAttr_t comm_attr = { .name="CommTask", .priority=osPriorityAboveNormal, .stack_size=2048 };
    osThreadNew(CommTask, NULL, &comm_attr);

    const osThreadAttr_t log_attr = { .name="LogTask", .priority=osPriorityLow, .stack_size=4096 };
    osThreadNew(LoggingTask, NULL, &log_attr);

    const osThreadAttr_t health_attr = { .name="HealthTask", .priority=osPriorityLow, .stack_size=2048 };
    osThreadNew(HealthTask, NULL, &health_attr);

    const osThreadAttr_t timer_attr = { .name="TimerDaemon", .priority=osPriorityHigh, .stack_size=2048 };
    osThreadNew(TimerDaemonTask, NULL, &timer_attr);

    /* register semaphores & mutex to drivers */
    ADS1115_SetSemaphore(sem_ads);
    MPU6050_SetSemaphore(sem_mpu);
    MCP4725_SetSemaphore(sem_mcp);
    LoRa_SetTxSemaphore(sem_lora_tx);

    ADS1115_SetI2CMutex(i2c_mutex);
    MPU6050_SetI2CMutex(i2c_mutex);
    MCP4725_SetI2CMutex(i2c_mutex);

    /* start scheduler */
    osKernelStart();

    /* should never reach here */
    for (;;) {}
}
void SystemClock_Config(void)
{
  RCC_OscInitTypeDef RCC_OscInitStruct = {0};
  RCC_ClkInitTypeDef RCC_ClkInitStruct = {0};

  /** Configure LSE Drive Capability
  */
  HAL_PWR_EnableBkUpAccess();
  __HAL_RCC_LSEDRIVE_CONFIG(RCC_LSEDRIVE_LOW);

  /** Configure the main internal regulator output voltage
  */
  __HAL_RCC_PWR_CLK_ENABLE();
  __HAL_PWR_VOLTAGESCALING_CONFIG(PWR_REGULATOR_VOLTAGE_SCALE1);

  /** Initializes the RCC Oscillators according to the specified parameters
  * in the RCC_OscInitTypeDef structure.
  */
  RCC_OscInitStruct.OscillatorType = RCC_OSCILLATORTYPE_HSE|RCC_OSCILLATORTYPE_LSE;
  RCC_OscInitStruct.HSEState = RCC_HSE_ON;
  RCC_OscInitStruct.LSEState = RCC_LSE_ON;
  RCC_OscInitStruct.PLL.PLLState = RCC_PLL_ON;
  RCC_OscInitStruct.PLL.PLLSource = RCC_PLLSOURCE_HSE;
  RCC_OscInitStruct.PLL.PLLM = 25;
  RCC_OscInitStruct.PLL.PLLN = 432;
  RCC_OscInitStruct.PLL.PLLP = RCC_PLLP_DIV2;
  RCC_OscInitStruct.PLL.PLLQ = 9;
  if (HAL_RCC_OscConfig(&RCC_OscInitStruct) != HAL_OK)
  {
    Error_Handler();
  }

  /** Activate the Over-Drive mode
  */
  if (HAL_PWREx_EnableOverDrive() != HAL_OK)
  {
    Error_Handler();
  }

  /** Initializes the CPU, AHB and APB buses clocks
  */
  RCC_ClkInitStruct.ClockType = RCC_CLOCKTYPE_HCLK|RCC_CLOCKTYPE_SYSCLK
                              |RCC_CLOCKTYPE_PCLK1|RCC_CLOCKTYPE_PCLK2;
  RCC_ClkInitStruct.SYSCLKSource = RCC_SYSCLKSOURCE_PLLCLK;
  RCC_ClkInitStruct.AHBCLKDivider = RCC_SYSCLK_DIV1;
  RCC_ClkInitStruct.APB1CLKDivider = RCC_HCLK_DIV4;
  RCC_ClkInitStruct.APB2CLKDivider = RCC_HCLK_DIV2;

  if (HAL_RCC_ClockConfig(&RCC_ClkInitStruct, FLASH_LATENCY_7) != HAL_OK)
  {
    Error_Handler();
  }
}

void Error_Handler(void)
{
  /* USER CODE BEGIN Error_Handler_Debug */
  /* User can add his own implementation to report the HAL error return state */
  __disable_irq();
  while (1)
  {
	  HAL_Delay(200);
  }
  /* USER CODE END Error_Handler_Debug */
}
#ifdef USE_FULL_ASSERT
/**
  * @brief  Reports the name of the source file and the source line number
  *         where the assert_param error has occurred.
  * @param  file: pointer to the source file name
  * @param  line: assert_param error line source number
  * @retval None
  */
void assert_failed(uint8_t *file, uint32_t line)
{
  /* USER CODE BEGIN 6 */
	printf("Assert %s:%lu\n", file, (unsigned long)line);
  /* User can add his own implementation to report the file name and line number,
     ex: printf("Wrong parameters value: file %s on line %d\r\n", file, line) */
  /* USER CODE END 6 */
}
#endif /* USE_FULL_ASSERT */

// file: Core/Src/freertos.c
/* USER CODE BEGIN Header */
/**
  ******************************************************************************
  * File Name          : freertos.c
  * Description        : Code for freertos applications
  ******************************************************************************
  * @attention
  *
  * Copyright (c) 2025 STMicroelectronics.
  * All rights reserved.
  *
  * This software is licensed under terms that can be found in the LICENSE file
  * in the root directory of this software component.
  * If no LICENSE file comes with this software, it is provided AS-IS.
  *
  ******************************************************************************
  */
/* USER CODE END Header */

#include "FreeRTOS.h"
#include "task.h"
#include "main.h"
#include "cmsis_os.h"

/* Definitions for defaultTask */
osThreadId_t defaultTaskHandle;
const osThreadAttr_t defaultTask_attributes = {
  .name = "defaultTask",
  .stack_size = 256 * 4,
  .priority = (osPriority_t) osPriorityNormal,
};

void StartDefaultTask(void *argument);

void MX_FREERTOS_Init(void); /* (MISRA C 2004 rule 8.1) */

/* USER CODE BEGIN PREPOSTSLEEP */
__weak void PreSleepProcessing(uint32_t *ulExpectedIdleTime)
{
/* place for user code */
}

__weak void PostSleepProcessing(uint32_t *ulExpectedIdleTime)
{
/* place for user code */
}
/* USER CODE END PREPOSTSLEEP */

void MX_FREERTOS_Init(void) {

  /* Create the thread(s) */
  /* creation of defaultTask */
  defaultTaskHandle = osThreadNew(StartDefaultTask, NULL, &defaultTask_attributes);

}

void StartDefaultTask(void *argument)
{
  for(;;)
  {
    osDelay(1);
  }
}
